VERSION ""

NS_ :

BS_:

BU_: Mppt Telemetry

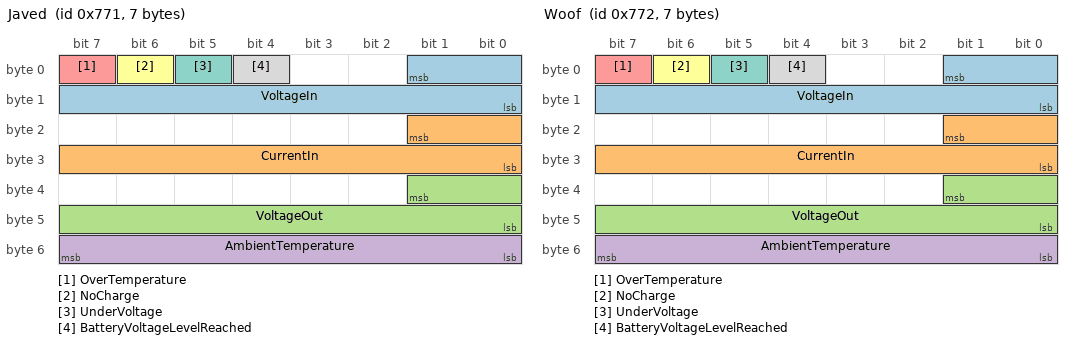
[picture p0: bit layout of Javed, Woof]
BO_ 1905 Javed: 7 Mppt
 SG_ VoltageIn : 1|10@0+ (0.15049,0) [0|153.95127] "V" Vector__XXX
 SG_ CurrentIn : 17|10@0+ (0.00872,0) [0|8.92056] "A" Vector__XXX
 SG_ VoltageOut : 33|10@0+ (1,0) [0|0] "" Vector__XXX
 SG_ AmbientTemperature : 55|8@0+ (1,0) [0|0] "" Vector__XXX
 SG_ OverTemperature : 7|1@0+ (1,0) [0|0] "" Vector__XXX
 SG_ NoCharge : 6|1@0+ (1,0) [0|0] "" Vector__XXX
 SG_ UnderVoltage : 5|1@0+ (1,0) [0|0] "" Vector__XXX
 SG_ BatteryVoltageLevelReached : 4|1@0+ (1,0) [0|0] "" Vector__XXX

BO_ 1906 Woof: 7 Mppt
 SG_ VoltageIn : 1|10@0+ (0.15049,0) [0|153.95127] "V" Vector__XXX
 SG_ CurrentIn : 17|10@0+ (0.00872,0) [0|8.92056] "A" Vector__XXX
 SG_ VoltageOut : 33|10@0+ (1,0) [0|0] "" Vector__XXX
 SG_ AmbientTemperature : 55|8@0+ (1,0) [0|0] "" Vector__XXX
 SG_ OverTemperature : 7|1@0+ (1,0) [0|0] "" Vector__XXX
 SG_ NoCharge : 6|1@0+ (1,0) [0|0] "" Vector__XXX
 SG_ UnderVoltage : 5|1@0+ (1,0) [0|0] "" Vector__XXX
 SG_ BatteryVoltageLevelReached : 4|1@0+ (1,0) [0|0] "" Vector__XXX

BO_ 1809 MpptPollJaved: 0 Telemetry

BO_ 1810 MpptPollWoof: 0 Telemetry

CM_ BU_ Mppt "The two MPPTs (maximum power point trackers), named Javed and Woof. Each takes power from part of the solar array and converts it to charge the battery. The request and reply IDs (0x710 + address, 0x770 + address), the 125 kbit/s bit rate and the 7-byte reply match the Drivetek MPPT. TODO: add the MPPT make and model (confirm it is a Drivetek), and which part of Peri's solar array each MPPT (Javed, Woof) is connected to.";
CM_ BU_ Telemetry "The telemetry board, which polls the MPPTs (see Telemetry.dbc).";
CM_ BO_ 1905 "Status of the MPPT named Javed, sent in reply to each MpptPollJaved request from the telemetry board (every mppt_update ms, Telemetry/config.txt). Not seen in any iESC 2026 recording, including Tests/data/NRT.BIN (qualifying) and the SD card logs, although the telemetry board polls both MPPTs every second (see Known limitations in the top-level README.md for what to check). TODO: add whether Peri still has these MPPTs; if not, remove this message.";
CM_ SG_ 1905 VoltageIn "Voltage from the solar array into this MPPT (scaling from the MPPT datasheet, as previously applied in live_power.py).";
CM_ SG_ 1905 CurrentIn "Current from the solar array into this MPPT (scaling from the MPPT datasheet, as previously applied in live_power.py).";
CM_ SG_ 1905 VoltageOut "Output voltage of this MPPT (battery side). TODO: add scaling and unit from the MPPT datasheet (still the raw value; check whether it is 208.79 mV per bit, as on similar MPPTs).";
CM_ SG_ 1905 AmbientTemperature "Temperature inside this MPPT. TODO: add scaling and unit from the MPPT datasheet (still the raw value).";
CM_ SG_ 1905 OverTemperature "1 if the MPPT reports that it is too hot.";
CM_ SG_ 1905 NoCharge "1 if the MPPT reports that it is not charging. TODO: add the conditions that set this flag, from the MPPT datasheet.";
CM_ SG_ 1905 UnderVoltage "1 if the MPPT reports an undervoltage. TODO: add whether this is the solar array (input) or battery (output) side, from the MPPT datasheet.";
CM_ SG_ 1905 BatteryVoltageLevelReached "1 if the battery has reached the MPPT's maximum output voltage, so the MPPT is limiting the charge.";
CM_ BO_ 1906 "Status of the MPPT named Woof, sent in reply to each MpptPollWoof request from the telemetry board (every mppt_update ms, Telemetry/config.txt). Not seen in any iESC 2026 recording, including Tests/data/NRT.BIN (qualifying) and the SD card logs, although the telemetry board polls both MPPTs every second (see Known limitations in the top-level README.md for what to check). TODO: add whether Peri still has these MPPTs; if not, remove this message.";
CM_ SG_ 1906 VoltageIn "Voltage from the solar array into this MPPT (scaling from the MPPT datasheet, as previously applied in live_power.py).";
CM_ SG_ 1906 CurrentIn "Current from the solar array into this MPPT (scaling from the MPPT datasheet, as previously applied in live_power.py).";
CM_ SG_ 1906 VoltageOut "Output voltage of this MPPT (battery side). TODO: add scaling and unit from the MPPT datasheet (still the raw value; check whether it is 208.79 mV per bit, as on similar MPPTs).";
CM_ SG_ 1906 AmbientTemperature "Temperature inside this MPPT. TODO: add scaling and unit from the MPPT datasheet (still the raw value).";
CM_ SG_ 1906 OverTemperature "1 if the MPPT reports that it is too hot.";
CM_ SG_ 1906 NoCharge "1 if the MPPT reports that it is not charging. TODO: add the conditions that set this flag, from the MPPT datasheet.";
CM_ SG_ 1906 UnderVoltage "1 if the MPPT reports an undervoltage. TODO: add whether this is the solar array (input) or battery (output) side, from the MPPT datasheet.";
CM_ SG_ 1906 BatteryVoltageLevelReached "1 if the battery has reached the MPPT's maximum output voltage, so the MPPT is limiting the charge.";
CM_ BO_ 1809 "Request from the telemetry board asking the Javed MPPT to send its status (message Javed). Sent every mppt_update ms (Telemetry/config.txt). The request carries no data.";
CM_ BO_ 1810 "Request from the telemetry board asking the Woof MPPT to send its status (message Woof). Sent every mppt_update ms (Telemetry/config.txt). The request carries no data.";
BA_DEF_ BO_  "GenMsgCycleTime" INT 0 65535;
BA_DEF_DEF_  "GenMsgCycleTime" 0;
BA_ "GenMsgCycleTime" BO_ 1809 1000;
BA_ "GenMsgCycleTime" BO_ 1810 1000;
BA_ "GenMsgCycleTime" BO_ 1905 1000;
BA_ "GenMsgCycleTime" BO_ 1906 1000;
VAL_ 1905 OverTemperature 0 "No" 1 "Yes" ;
VAL_ 1905 NoCharge 0 "No" 1 "Yes" ;
VAL_ 1905 UnderVoltage 0 "No" 1 "Yes" ;
VAL_ 1905 BatteryVoltageLevelReached 0 "No" 1 "Yes" ;
VAL_ 1906 OverTemperature 0 "No" 1 "Yes" ;
VAL_ 1906 NoCharge 0 "No" 1 "Yes" ;
VAL_ 1906 UnderVoltage 0 "No" 1 "Yes" ;
VAL_ 1906 BatteryVoltageLevelReached 0 "No" 1 "Yes" ;
